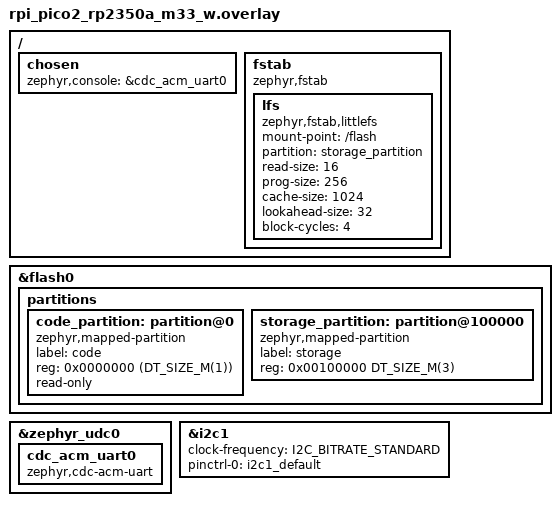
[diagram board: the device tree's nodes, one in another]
/*
 * Copyright (c) 2026 MASSDRIVER EI (massdriver.space)
 *
 * SPDX-License-Identifier: Apache-2.0
 */

/ {
	chosen {
		/* Use USB CDC ACM as the console. */
		zephyr,console = &cdc_acm_uart0;
	};

	fstab {
		compatible = "zephyr,fstab";
		lfs: lfs {
			compatible = "zephyr,fstab,littlefs";
			mount-point = "/flash";
			partition = <&storage_partition>;
			read-size=<16>;
			prog-size=<256>;
			cache-size=<1024>;
			lookahead-size=<32>;
			block-cycles=<4>;
		};
	};
};

/delete-node/ &code_partition;
&flash0 {
	partitions {
		ranges;
		#address-cells = <1>;
		#size-cells = <1>;

		code_partition: partition@0 {
			compatible = "zephyr,mapped-partition";
			label = "code";
			reg = <0x0000000 (DT_SIZE_M(1))>;
			read-only;
		};

		storage_partition: partition@100000 {
			compatible = "zephyr,mapped-partition";
			label = "storage";
			reg = <0x00100000 DT_SIZE_M(3)>;
		};
	};
};

&zephyr_udc0 {
	cdc_acm_uart0: cdc_acm_uart0 {
		compatible = "zephyr,cdc-acm-uart";
	};
};

&i2c1 {
	clock-frequency = <I2C_BITRATE_STANDARD>;
	status = "okay";
	pinctrl-0 = <&i2c1_default>;
	pinctrl-names = "default";
};
